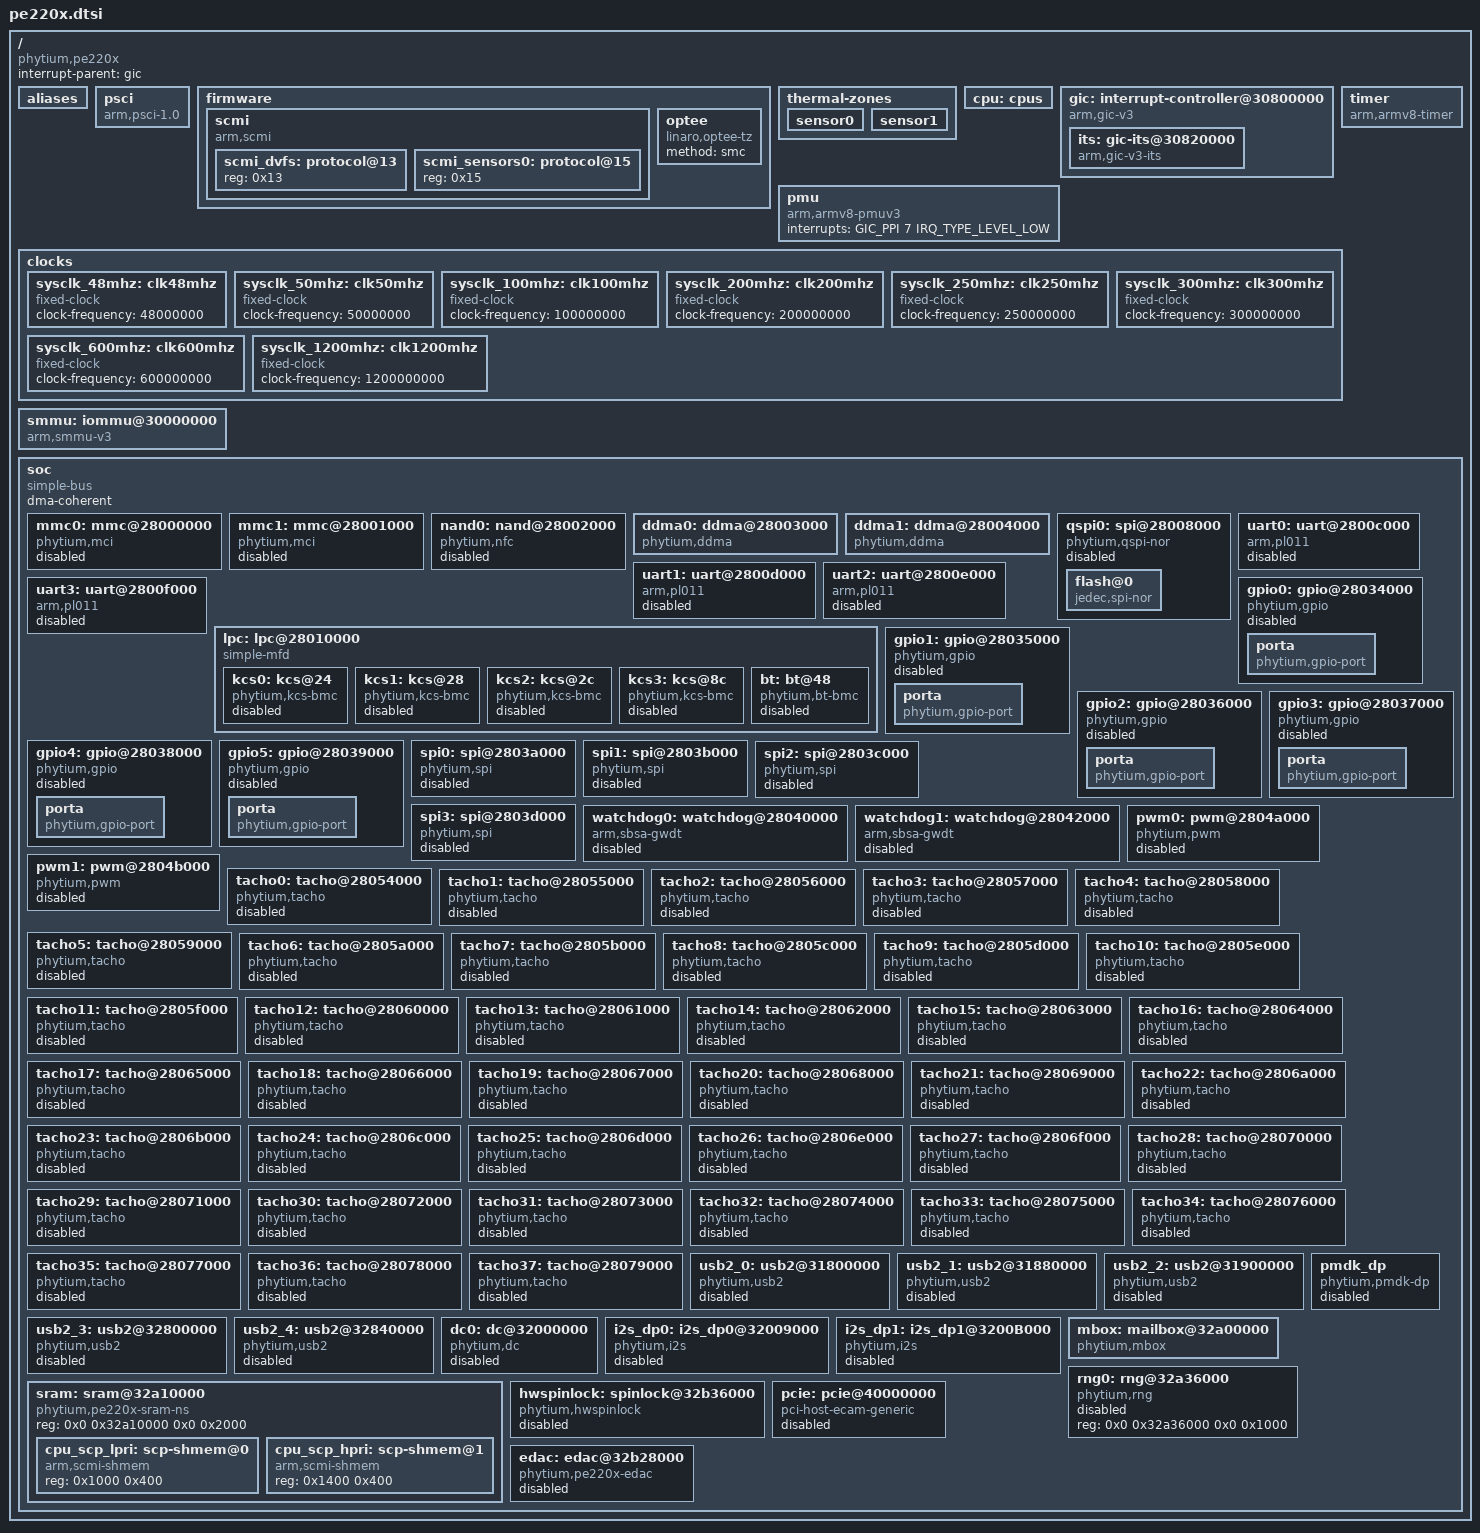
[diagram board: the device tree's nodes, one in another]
// SPDX-License-Identifier: GPL-2.0
/*
 * dts file for Phytium Pe220x SoC
 *
 * Copyright (c) 2021-2023 Phytium Technology Co., Ltd.
 */

#include <dt-bindings/interrupt-controller/arm-gic.h>

/ {
	compatible = "phytium,pe220x";
	interrupt-parent = <&gic>;
	#address-cells = <2>;
	#size-cells = <2>;

	aliases {
		serial0 = &uart0;
		serial1 = &uart1;
		serial2 = &uart2;
		serial3 = &uart3;
	};

	psci {
		compatible   = "arm,psci-1.0";
		method       = "smc";
		cpu_suspend  = <0xc4000001>;
		cpu_off      = <0x84000002>;
		cpu_on       = <0xc4000003>;
		sys_poweroff = <0x84000008>;
		sys_reset    = <0x84000009>;
	};

	firmware {
		scmi: scmi {
			compatible = "arm,scmi";
			mboxes = <&mbox 0>;
			mbox-names = "tx";
			shmem = <&cpu_scp_hpri>;
			#address-cells = <1>;
			#size-cells = <0>;

			scmi_dvfs: protocol@13 {
				reg = <0x13>;
				#clock-cells = <1>;
			};

			scmi_sensors0: protocol@15 {
				reg = <0x15>;
				#thermal-sensor-cells = <1>;
			};
		};
		optee {
			compatible = "linaro,optee-tz";
			method = "smc";
		};
	};

	thermal-zones {
		sensor0 {
			polling-delay-passive = <100>;
			polling-delay = <1000>;
			thermal-sensors = <&scmi_sensors0 0>;
		};

		sensor1 {
			polling-delay-passive = <100>;
			polling-delay = <1000>;
			thermal-sensors = <&scmi_sensors0 1>;
		};
	};

	cpu: cpus {
		#address-cells = <0x2>;
		#size-cells = <0x0>;
	};

	gic: interrupt-controller@30800000 {
		compatible = "arm,gic-v3";
		#interrupt-cells = <3>;
		#address-cells = <2>;
		#size-cells = <2>;
		ranges;
		interrupt-controller;
		reg = <0x0 0x30800000 0 0x20000>,	/* GICD */
			  <0x0 0x30880000 0 0x80000>,	/* GICR */
			  <0x0 0x30840000 0 0x10000>,	/* GICC */
			  <0x0 0x30850000 0 0x10000>,	/* GICH */
			  <0x0 0x30860000 0 0x10000>;	/* GICV */
		interrupts = <GIC_PPI 9 IRQ_TYPE_LEVEL_LOW>;

		its: gic-its@30820000 {
			compatible = "arm,gic-v3-its";
			msi-controller;
			reg = <0x0 0x30820000 0x0 0x20000>;
		};
	};

	pmu {
		compatible = "arm,armv8-pmuv3";
		interrupts = <GIC_PPI 7 IRQ_TYPE_LEVEL_LOW>;
	};

	timer {
		compatible = "arm,armv8-timer";
		interrupts = <GIC_PPI 13 IRQ_TYPE_LEVEL_LOW>,
				 <GIC_PPI 14 IRQ_TYPE_LEVEL_LOW>,
				 <GIC_PPI 11 IRQ_TYPE_LEVEL_LOW>,
				 <GIC_PPI 10 IRQ_TYPE_LEVEL_LOW>;
		clock-frequency = <50000000>;
	};

	clocks {
		#address-cells = <2>;
		#size-cells = <2>;
		ranges;

		sysclk_48mhz: clk48mhz {
			compatible = "fixed-clock";
			#clock-cells = <0>;
			clock-frequency = <48000000>;
		};

		sysclk_50mhz: clk50mhz {
			compatible = "fixed-clock";
			#clock-cells = <0>;
			clock-frequency = <50000000>;
		};

		sysclk_100mhz: clk100mhz {
			compatible = "fixed-clock";
			#clock-cells = <0>;
			clock-frequency = <100000000>;
		};

		sysclk_200mhz: clk200mhz {
			compatible = "fixed-clock";
			#clock-cells = <0>;
			clock-frequency = <200000000>;
		};

		sysclk_250mhz: clk250mhz {
			compatible = "fixed-clock";
			#clock-cells = <0>;
			clock-frequency = <250000000>;
		};

		sysclk_300mhz: clk300mhz {
			compatible = "fixed-clock";
			#clock-cells = <0>;
			clock-frequency = <300000000>;
		};

		sysclk_600mhz: clk600mhz {
			compatible = "fixed-clock";
			#clock-cells = <0>;
			clock-frequency = <600000000>;
		};

		sysclk_1200mhz: clk1200mhz {
			compatible = "fixed-clock";
			#clock-cells = <0>;
			clock-frequency = <1200000000>;
		};
	};

	smmu: iommu@30000000 {
		compatible = "arm,smmu-v3";
		reg = <0x0 0x30000000 0x0 0x800000>;
		interrupts = <GIC_SPI 240 IRQ_TYPE_EDGE_RISING>,
				 <GIC_SPI 239 IRQ_TYPE_EDGE_RISING>,
				 <GIC_SPI 236 IRQ_TYPE_EDGE_RISING>,
				 <GIC_SPI 242 IRQ_TYPE_EDGE_RISING>;
		interrupt-names = "eventq", "priq", "cmdq-sync", "gerror";
		dma-coherent;
		#iommu-cells = <1>;
	};

	soc: soc {
		compatible = "simple-bus";
		#address-cells = <2>;
		#size-cells = <2>;
		dma-coherent;
		ranges;

		mmc0: mmc@28000000 {
			compatible = "phytium,mci";
			reg = <0x0 0x28000000 0x0 0x1000>;
			interrupts = <GIC_SPI 72 IRQ_TYPE_LEVEL_HIGH>;
			clocks = <&sysclk_1200mhz>;
			clock-names = "phytium_mci_clk";
			status = "disabled";
		};

		mmc1: mmc@28001000 {
			compatible = "phytium,mci";
			reg = <0x0 0x28001000 0x0 0x1000>;
			interrupts = <GIC_SPI 73 IRQ_TYPE_LEVEL_HIGH>;
			clocks = <&sysclk_1200mhz>;
			clock-names = "phytium_mci_clk";
			status = "disabled";
		};

		nand0: nand@28002000 {
			compatible = "phytium,nfc";
			reg = <0x0 0x28002000 0x0 0x1000>;
			interrupts = <GIC_SPI 74 IRQ_TYPE_LEVEL_HIGH>;
			status = "disabled";
		};

		ddma0: ddma@28003000 {
			compatible = "phytium,ddma";
			reg = <0x0 0x28003000 0x0 0x1000>;
			interrupts = <GIC_SPI 75 IRQ_TYPE_LEVEL_HIGH>;
			#dma-cells = <2>;
			dma-channels = <8>;
		};

		ddma1: ddma@28004000 {
			compatible = "phytium,ddma";
			reg = <0x0 0x28004000 0x0 0x1000>;
			interrupts = <GIC_SPI 76 IRQ_TYPE_LEVEL_HIGH>;
			#dma-cells = <2>;
			dma-channels = <8>;
		};

		qspi0: spi@28008000 {
			compatible = "phytium,qspi-nor";
			reg = <0x0 0x28008000 0x0	  0x1000>,
				  <0x0		  0x0 0x0 0x0fffffff>;
			reg-names = "qspi", "qspi_mm";
			clocks = <&sysclk_300mhz>;
			status = "disabled";
			#address-cells = <1>;
			#size-cells = <0>;

			flash@0 {
				compatible = "jedec,spi-nor";
				reg = <0x00>;
				spi-rx-bus-width = <1>;
				spi-max-frequency = <50000000>;
			};
		};

		uart0: uart@2800c000 {
			compatible = "arm,pl011","arm,primecell";
			reg = <0x0 0x2800c000 0x0 0x1000>;
			interrupts = <GIC_SPI 83 IRQ_TYPE_LEVEL_HIGH>;
			clocks = <&sysclk_100mhz &sysclk_100mhz>;
			clock-names = "uartclk", "apb_pclk";
			status = "disabled";
		};

		uart1: uart@2800d000 {
			compatible = "arm,pl011","arm,primecell";
			reg = <0x0 0x2800d000 0x0 0x1000>;
			interrupts = <GIC_SPI 84 IRQ_TYPE_LEVEL_HIGH>;
			clocks = <&sysclk_100mhz &sysclk_100mhz>;
			clock-names = "uartclk", "apb_pclk";
			status = "disabled";
		};

		uart2: uart@2800e000 {
			compatible = "arm,pl011","arm,primecell";
			reg = <0x0 0x2800e000 0x0 0x1000>;
			interrupts = <GIC_SPI 85 IRQ_TYPE_LEVEL_HIGH>;
			clocks = <&sysclk_100mhz &sysclk_100mhz>;
			clock-names = "uartclk", "apb_pclk";
			status = "disabled";
		};

		uart3: uart@2800f000 {
			compatible = "arm,pl011","arm,primecell";
			reg = <0x0 0x2800f000 0x0 0x1000>;
			interrupts = <GIC_SPI 86 IRQ_TYPE_LEVEL_HIGH>;
			clocks = <&sysclk_100mhz &sysclk_100mhz>;
			clock-names = "uartclk", "apb_pclk";
			status = "disabled";
		};

		lpc: lpc@28010000 {
			compatible = "simple-mfd", "syscon";
			reg = <0x0 0x28010000 0x0 0x1000>;
			reg-io-width = <4>;

			#address-cells = <1>;
			#size-cells = <1>;
			ranges = <0x0 0x0 0x28010000 0x1000>;

			kcs0: kcs@24 {
				compatible = "phytium,kcs-bmc";
				reg = <0x24 0x1>, <0x30 0x1>, <0x3c 0x1>;
				interrupts = <GIC_SPI 88 IRQ_TYPE_LEVEL_HIGH>;
				status = "disabled";
			};

			kcs1: kcs@28 {
				compatible = "phytium,kcs-bmc";
				reg = <0x28 0x1>, <0x34 0x1>, <0x40 0x1>;
				interrupts = <GIC_SPI 88 IRQ_TYPE_LEVEL_HIGH>;
				status = "disabled";
			};

			kcs2: kcs@2c {
				compatible = "phytium,kcs-bmc";
				reg = <0x2c 0x1>, <0x38 0x1>, <0x44 0x1>;
				interrupts = <GIC_SPI 88 IRQ_TYPE_LEVEL_HIGH>;
				status = "disabled";
			};

			kcs3: kcs@8c {
				compatible = "phytium,kcs-bmc";
				reg = <0x8c 0x1>, <0x90 0x1>, <0x94 0x1>;
				interrupts = <GIC_SPI 88 IRQ_TYPE_LEVEL_HIGH>;
				status = "disabled";
			};

			bt: bt@48 {
				compatible = "phytium,bt-bmc";
				reg = <0x48 0x20>;
				interrupts = <GIC_SPI 88 IRQ_TYPE_LEVEL_HIGH>;
				status = "disabled";
			};
		};

		/* MIO */

		gpio0: gpio@28034000 {
			compatible = "phytium,gpio";
			reg = <0x0 0x28034000 0x0 0x1000>;
			interrupts = <GIC_SPI 108 IRQ_TYPE_LEVEL_HIGH>,
					 <GIC_SPI 109 IRQ_TYPE_LEVEL_HIGH>,
					 <GIC_SPI 110 IRQ_TYPE_LEVEL_HIGH>,
					 <GIC_SPI 111 IRQ_TYPE_LEVEL_HIGH>,
					 <GIC_SPI 112 IRQ_TYPE_LEVEL_HIGH>,
					 <GIC_SPI 113 IRQ_TYPE_LEVEL_HIGH>,
					 <GIC_SPI 114 IRQ_TYPE_LEVEL_HIGH>,
					 <GIC_SPI 115 IRQ_TYPE_LEVEL_HIGH>,
					 <GIC_SPI 116 IRQ_TYPE_LEVEL_HIGH>,
					 <GIC_SPI 117 IRQ_TYPE_LEVEL_HIGH>,
					 <GIC_SPI 118 IRQ_TYPE_LEVEL_HIGH>,
					 <GIC_SPI 119 IRQ_TYPE_LEVEL_HIGH>,
					 <GIC_SPI 120 IRQ_TYPE_LEVEL_HIGH>,
					 <GIC_SPI 121 IRQ_TYPE_LEVEL_HIGH>,
					 <GIC_SPI 122 IRQ_TYPE_LEVEL_HIGH>,
					 <GIC_SPI 123 IRQ_TYPE_LEVEL_HIGH>;
			gpio-controller;
			#gpio-cells = <2>;
			#address-cells = <1>;
			#size-cells = <0>;
			status = "disabled";

			porta {
				compatible = "phytium,gpio-port";
				reg = <0>;
				ngpios = <16>;
			};
		};

		gpio1: gpio@28035000 {
			compatible = "phytium,gpio";
			reg = <0x0 0x28035000 0x0 0x1000>;
			interrupts = <GIC_SPI 124 IRQ_TYPE_LEVEL_HIGH>,
					 <GIC_SPI 125 IRQ_TYPE_LEVEL_HIGH>,
					 <GIC_SPI 126 IRQ_TYPE_LEVEL_HIGH>,
					 <GIC_SPI 127 IRQ_TYPE_LEVEL_HIGH>,
					 <GIC_SPI 128 IRQ_TYPE_LEVEL_HIGH>,
					 <GIC_SPI 129 IRQ_TYPE_LEVEL_HIGH>,
					 <GIC_SPI 130 IRQ_TYPE_LEVEL_HIGH>,
					 <GIC_SPI 131 IRQ_TYPE_LEVEL_HIGH>,
					 <GIC_SPI 132 IRQ_TYPE_LEVEL_HIGH>,
					 <GIC_SPI 133 IRQ_TYPE_LEVEL_HIGH>,
					 <GIC_SPI 134 IRQ_TYPE_LEVEL_HIGH>,
					 <GIC_SPI 135 IRQ_TYPE_LEVEL_HIGH>,
					 <GIC_SPI 136 IRQ_TYPE_LEVEL_HIGH>,
					 <GIC_SPI 137 IRQ_TYPE_LEVEL_HIGH>,
					 <GIC_SPI 138 IRQ_TYPE_LEVEL_HIGH>,
					 <GIC_SPI 139 IRQ_TYPE_LEVEL_HIGH>;
			gpio-controller;
			#gpio-cells = <2>;
			#address-cells = <1>;
			#size-cells = <0>;
			status = "disabled";

			porta {
				compatible = "phytium,gpio-port";
				reg = <0>;
				ngpios = <16>;
			};
		};

		gpio2: gpio@28036000 {
			compatible = "phytium,gpio";
			reg = <0x0 0x28036000 0x0 0x1000>;
			interrupts = <GIC_SPI 140 IRQ_TYPE_LEVEL_HIGH>,
					 <GIC_SPI 141 IRQ_TYPE_LEVEL_HIGH>,
					 <GIC_SPI 142 IRQ_TYPE_LEVEL_HIGH>,
					 <GIC_SPI 143 IRQ_TYPE_LEVEL_HIGH>,
					 <GIC_SPI 144 IRQ_TYPE_LEVEL_HIGH>,
					 <GIC_SPI 145 IRQ_TYPE_LEVEL_HIGH>,
					 <GIC_SPI 146 IRQ_TYPE_LEVEL_HIGH>,
					 <GIC_SPI 147 IRQ_TYPE_LEVEL_HIGH>,
					 <GIC_SPI 148 IRQ_TYPE_LEVEL_HIGH>,
					 <GIC_SPI 149 IRQ_TYPE_LEVEL_HIGH>,
					 <GIC_SPI 150 IRQ_TYPE_LEVEL_HIGH>,
					 <GIC_SPI 151 IRQ_TYPE_LEVEL_HIGH>,
					 <GIC_SPI 152 IRQ_TYPE_LEVEL_HIGH>,
					 <GIC_SPI 153 IRQ_TYPE_LEVEL_HIGH>,
					 <GIC_SPI 154 IRQ_TYPE_LEVEL_HIGH>,
					 <GIC_SPI 155 IRQ_TYPE_LEVEL_HIGH>;
			gpio-controller;
			#gpio-cells = <2>;
			#address-cells = <1>;
			#size-cells = <0>;
			status = "disabled";

			porta {
				compatible = "phytium,gpio-port";
				reg = <0>;
				ngpios = <16>;
			};
		};

		gpio3: gpio@28037000 {
			compatible = "phytium,gpio";
			reg = <0x0 0x28037000 0x0 0x1000>;
			interrupts = <GIC_SPI 156 IRQ_TYPE_LEVEL_HIGH>;
			gpio-controller;
			#gpio-cells = <2>;
			#address-cells = <1>;
			#size-cells = <0>;
			status = "disabled";

			porta {
				compatible = "phytium,gpio-port";
				reg = <0>;
				ngpios = <16>;
			};
		};

		gpio4: gpio@28038000 {
			compatible = "phytium,gpio";
			reg = <0x0 0x28038000 0x0 0x1000>;
			interrupts = <GIC_SPI 157 IRQ_TYPE_LEVEL_HIGH>;
			gpio-controller;
			#gpio-cells = <2>;
			#address-cells = <1>;
			#size-cells = <0>;
			status = "disabled";

			porta {
				compatible = "phytium,gpio-port";
				reg = <0>;
				ngpios = <16>;
			};
		};

		gpio5: gpio@28039000 {
			compatible = "phytium,gpio";
			reg = <0x0 0x28039000 0x0 0x1000>;
			interrupts = <GIC_SPI 158 IRQ_TYPE_LEVEL_HIGH>;
			gpio-controller;
			#gpio-cells = <2>;
			#address-cells = <1>;
			#size-cells = <0>;
			status = "disabled";

			porta {
				compatible = "phytium,gpio-port";
				reg = <0>;
				ngpios = <16>;
			};
		};

		spi0: spi@2803a000 {
			compatible = "phytium,spi";
			reg = <0x0 0x2803a000 0x0 0x1000>;
			interrupts = <GIC_SPI 159 IRQ_TYPE_LEVEL_HIGH>;
			clocks = <&sysclk_50mhz>;
			num-cs = <4>;
			#address-cells = <1>;
			#size-cells = <0>;
			status = "disabled";
		};

		spi1: spi@2803b000 {
			compatible = "phytium,spi";
			reg = <0x0 0x2803b000 0x0 0x1000>;
			interrupts = <GIC_SPI 160 IRQ_TYPE_LEVEL_HIGH>;
			clocks = <&sysclk_50mhz>;
			num-cs = <4>;
			#address-cells = <1>;
			#size-cells = <0>;
			status = "disabled";
		};

		spi2: spi@2803c000 {
			compatible = "phytium,spi";
			reg = <0x0 0x2803c000 0x0 0x1000>;
			interrupts = <GIC_SPI 161 IRQ_TYPE_LEVEL_HIGH>;
			clocks = <&sysclk_50mhz>;
			num-cs = <4>;
			#address-cells = <1>;
			#size-cells = <0>;
			status = "disabled";
		};

		spi3: spi@2803d000 {
			compatible = "phytium,spi";
			reg = <0x0 0x2803d000 0x0 0x1000>;
			interrupts = <GIC_SPI 162 IRQ_TYPE_LEVEL_HIGH>;
			clocks = <&sysclk_50mhz>;
			num-cs = <4>;
			#address-cells = <1>;
			#size-cells = <0>;
			status = "disabled";
		};

		watchdog0: watchdog@28040000 {
			compatible = "arm,sbsa-gwdt";
			reg = <0x0 0x28041000 0x0 0x1000>,
				  <0x0 0x28040000 0x0 0x1000>;
			interrupts = <GIC_SPI 164 IRQ_TYPE_LEVEL_HIGH>;
			timeout-sec = <30>;
			status = "disabled";
		};

		watchdog1: watchdog@28042000 {
			compatible = "arm,sbsa-gwdt";
			reg = <0x0 0x28043000 0x0 0x1000>,
				  <0x0 0x28042000 0x0 0x1000>;
			interrupts = <GIC_SPI 165 IRQ_TYPE_LEVEL_HIGH>;
			timeout-sec = <30>;
			status = "disabled";
		};

		pwm0: pwm@2804a000 {
			compatible = "phytium,pwm";
			reg = <0x0 0x2804a000 0x0 0x1000>;
			interrupts = <GIC_SPI 173 IRQ_TYPE_LEVEL_HIGH>;
			clocks = <&sysclk_50mhz>;
			status = "disabled";
		};

		pwm1: pwm@2804b000 {
			compatible = "phytium,pwm";
			reg = <0x0 0x2804b000 0x0 0x1000>;
			interrupts = <GIC_SPI 174 IRQ_TYPE_LEVEL_HIGH>;
			clocks = <&sysclk_50mhz>;
			status = "disabled";
		};

		tacho0: tacho@28054000 {
			compatible = "phytium,tacho";
			reg = <0x0 0x28054000 0x0 0x1000>;
			interrupts = <GIC_SPI 194 IRQ_TYPE_LEVEL_HIGH>;
			clocks = <&sysclk_50mhz >;
			status = "disabled";
		};

		tacho1: tacho@28055000 {
			compatible = "phytium,tacho";
			reg = <0x0 0x28055000 0x0 0x1000>;
			interrupts = <GIC_SPI 195 IRQ_TYPE_LEVEL_HIGH>;
			clocks = <&sysclk_50mhz >;
			status = "disabled";
		};

		tacho2: tacho@28056000 {
			compatible = "phytium,tacho";
			reg = <0x0 0x28056000 0x0 0x1000>;
			interrupts = <GIC_SPI 196 IRQ_TYPE_LEVEL_HIGH>;
			clocks = <&sysclk_50mhz >;
			status = "disabled";
		};

		tacho3: tacho@28057000 {
			compatible = "phytium,tacho";
			reg = <0x0 0x28057000 0x0 0x1000>;
			interrupts = <GIC_SPI 197 IRQ_TYPE_LEVEL_HIGH>;
			clocks = <&sysclk_50mhz >;
			status = "disabled";
		};

		tacho4: tacho@28058000 {
			compatible = "phytium,tacho";
			reg = <0x0 0x28058000 0x0 0x1000>;
			interrupts = <GIC_SPI 198 IRQ_TYPE_LEVEL_HIGH>;
			clocks = <&sysclk_50mhz >;
			status = "disabled";
		};

		tacho5: tacho@28059000 {
			compatible = "phytium,tacho";
			reg = <0x0 0x28059000 0x0 0x1000>;
			interrupts = <GIC_SPI 199 IRQ_TYPE_LEVEL_HIGH>;
			clocks = <&sysclk_50mhz >;
			status = "disabled";
		};

		tacho6: tacho@2805a000 {
			compatible = "phytium,tacho";
			reg = <0x0 0x2805a000 0x0 0x1000>;
			interrupts = <GIC_SPI 200 IRQ_TYPE_LEVEL_HIGH>;
			clocks = <&sysclk_50mhz >;
			status = "disabled";
		};

		tacho7: tacho@2805b000 {
			compatible = "phytium,tacho";
			reg = <0x0 0x2805b000 0x0 0x1000>;
			interrupts = <GIC_SPI 201 IRQ_TYPE_LEVEL_HIGH>;
			clocks = <&sysclk_50mhz >;
			status = "disabled";
		};

		tacho8: tacho@2805c000 {
			compatible = "phytium,tacho";
			reg = <0x0 0x2805c000 0x0 0x1000>;
			interrupts = <GIC_SPI 202 IRQ_TYPE_LEVEL_HIGH>;
			clocks = <&sysclk_50mhz >;
			status = "disabled";
		};

		tacho9: tacho@2805d000 {
			compatible = "phytium,tacho";
			reg = <0x0 0x2805d000 0x0 0x1000>;
			interrupts = <GIC_SPI 203 IRQ_TYPE_LEVEL_HIGH>;
			clocks = <&sysclk_50mhz >;
			status = "disabled";
		};

		tacho10: tacho@2805e000 {
			compatible = "phytium,tacho";
			reg = <0x0 0x2805e000 0x0 0x1000>;
			interrupts = <GIC_SPI 204 IRQ_TYPE_LEVEL_HIGH>;
			clocks = <&sysclk_50mhz >;
			status = "disabled";
		};

		tacho11: tacho@2805f000 {
			compatible = "phytium,tacho";
			reg = <0x0 0x2805f000 0x0 0x1000>;
			interrupts = <GIC_SPI 205 IRQ_TYPE_LEVEL_HIGH>;
			clocks = <&sysclk_50mhz >;
			status = "disabled";
		};

		tacho12: tacho@28060000 {
			compatible = "phytium,tacho";
			reg = <0x0 0x28060000 0x0 0x1000>;
			interrupts = <GIC_SPI 206 IRQ_TYPE_LEVEL_HIGH>;
			clocks = <&sysclk_50mhz >;
			status = "disabled";
		};

		tacho13: tacho@28061000 {
			compatible = "phytium,tacho";
			reg = <0x0 0x28061000 0x0 0x1000>;
			interrupts = <GIC_SPI 207 IRQ_TYPE_LEVEL_HIGH>;
			clocks = <&sysclk_50mhz >;
			status = "disabled";
		};

		tacho14: tacho@28062000 {
			compatible = "phytium,tacho";
			reg = <0x0 0x28062000 0x0 0x1000>;
			interrupts = <GIC_SPI 208 IRQ_TYPE_LEVEL_HIGH>;
			clocks = <&sysclk_50mhz >;
			status = "disabled";
		};

		tacho15: tacho@28063000 {
			compatible = "phytium,tacho";
			reg = <0x0 0x28063000 0x0 0x1000>;
			interrupts = <GIC_SPI 209 IRQ_TYPE_LEVEL_HIGH>;
			clocks = <&sysclk_50mhz >;
			status = "disabled";
		};

		tacho16: tacho@28064000 {
			compatible = "phytium,tacho";
			reg = <0x0 0x28064000 0x0 0x1000>;
			interrupts = <GIC_SPI 210 IRQ_TYPE_LEVEL_HIGH>;
			clocks = <&sysclk_50mhz >;
			status = "disabled";
		};

		tacho17: tacho@28065000 {
			compatible = "phytium,tacho";
			reg = <0x0 0x28065000 0x0 0x1000>;
			interrupts = <GIC_SPI 211 IRQ_TYPE_LEVEL_HIGH>;
			clocks = <&sysclk_50mhz >;
			status = "disabled";
		};

		tacho18: tacho@28066000 {
			compatible = "phytium,tacho";
			reg = <0x0 0x28066000 0x0 0x1000>;
			interrupts = <GIC_SPI 212 IRQ_TYPE_LEVEL_HIGH>;
			clocks = <&sysclk_50mhz >;
			status = "disabled";
		};

		tacho19: tacho@28067000 {
			compatible = "phytium,tacho";
			reg = <0x0 0x28067000 0x0 0x1000>;
			interrupts = <GIC_SPI 213 IRQ_TYPE_LEVEL_HIGH>;
			clocks = <&sysclk_50mhz >;
			status = "disabled";
		};

		tacho20: tacho@28068000 {
			compatible = "phytium,tacho";
			reg = <0x0 0x28068000 0x0 0x1000>;
			interrupts = <GIC_SPI 214 IRQ_TYPE_LEVEL_HIGH>;
			clocks = <&sysclk_50mhz >;
			status = "disabled";
		};

		tacho21: tacho@28069000 {
			compatible = "phytium,tacho";
			reg = <0x0 0x28069000 0x0 0x1000>;
			interrupts = <GIC_SPI 215 IRQ_TYPE_LEVEL_HIGH>;
			clocks = <&sysclk_50mhz >;
			status = "disabled";
		};

		tacho22: tacho@2806a000 {
			compatible = "phytium,tacho";
			reg = <0x0 0x2806a000 0x0 0x1000>;
			interrupts = <GIC_SPI 216 IRQ_TYPE_LEVEL_HIGH>;
			clocks = <&sysclk_50mhz >;
			status = "disabled";
		};

		tacho23: tacho@2806b000 {
			compatible = "phytium,tacho";
			reg = <0x0 0x2806b000 0x0 0x1000>;
			interrupts = <GIC_SPI 217 IRQ_TYPE_LEVEL_HIGH>;
			clocks = <&sysclk_50mhz >;
			status = "disabled";
		};

		tacho24: tacho@2806c000 {
			compatible = "phytium,tacho";
			reg = <0x0 0x2806c000 0x0 0x1000>;
			interrupts = <GIC_SPI 218 IRQ_TYPE_LEVEL_HIGH>;
			clocks = <&sysclk_50mhz >;
			status = "disabled";
		};

		tacho25: tacho@2806d000 {
			compatible = "phytium,tacho";
			reg = <0x0 0x2806d000 0x0 0x1000>;
			interrupts = <GIC_SPI 219 IRQ_TYPE_LEVEL_HIGH>;
			clocks = <&sysclk_50mhz >;
			status = "disabled";
		};

		tacho26: tacho@2806e000 {
			compatible = "phytium,tacho";
			reg = <0x0 0x2806e000 0x0 0x1000>;
			interrupts = <GIC_SPI 220 IRQ_TYPE_LEVEL_HIGH>;
			clocks = <&sysclk_50mhz >;
			status = "disabled";
		};

		tacho27: tacho@2806f000 {
			compatible = "phytium,tacho";
			reg = <0x0 0x2806f000 0x0 0x1000>;
			interrupts = <GIC_SPI 221 IRQ_TYPE_LEVEL_HIGH>;
			clocks = <&sysclk_50mhz >;
			status = "disabled";
		};

		tacho28: tacho@28070000 {
			compatible = "phytium,tacho";
			reg = <0x0 0x28070000 0x0 0x1000>;
			interrupts = <GIC_SPI 222 IRQ_TYPE_LEVEL_HIGH>;
			clocks = <&sysclk_50mhz >;
			status = "disabled";
		};

		tacho29: tacho@28071000 {
			compatible = "phytium,tacho";
			reg = <0x0 0x28071000 0x0 0x1000>;
			interrupts = <GIC_SPI 223 IRQ_TYPE_LEVEL_HIGH>;
			clocks = <&sysclk_50mhz >;
			status = "disabled";
		};

		tacho30: tacho@28072000 {
			compatible = "phytium,tacho";
			reg = <0x0 0x28072000 0x0 0x1000>;
			interrupts = <GIC_SPI 224 IRQ_TYPE_LEVEL_HIGH>;
			clocks = <&sysclk_50mhz >;
			status = "disabled";
		};

		tacho31: tacho@28073000 {
			compatible = "phytium,tacho";
			reg = <0x0 0x28073000 0x0 0x1000>;
			interrupts = <GIC_SPI 225 IRQ_TYPE_LEVEL_HIGH>;
			clocks = <&sysclk_50mhz >;
			status = "disabled";
		};

		tacho32: tacho@28074000 {
			compatible = "phytium,tacho";
			reg = <0x0 0x28074000 0x0 0x1000>;
			interrupts = <GIC_SPI 226 IRQ_TYPE_LEVEL_HIGH>;
			clocks = <&sysclk_50mhz >;
			status = "disabled";
		};

		tacho33: tacho@28075000 {
			compatible = "phytium,tacho";
			reg = <0x0 0x28075000 0x0 0x1000>;
			interrupts = <GIC_SPI 227 IRQ_TYPE_LEVEL_HIGH>;
			clocks = <&sysclk_50mhz >;
			status = "disabled";
		};

		tacho34: tacho@28076000 {
			compatible = "phytium,tacho";
			reg = <0x0 0x28076000 0x0 0x1000>;
			interrupts = <GIC_SPI 228 IRQ_TYPE_LEVEL_HIGH>;
			clocks = <&sysclk_50mhz >;
			status = "disabled";
		};

		tacho35: tacho@28077000 {
			compatible = "phytium,tacho";
			reg = <0x0 0x28077000 0x0 0x1000>;
			interrupts = <GIC_SPI 229 IRQ_TYPE_LEVEL_HIGH>;
			clocks = <&sysclk_50mhz >;
			status = "disabled";
		};

		tacho36: tacho@28078000 {
			compatible = "phytium,tacho";
			reg = <0x0 0x28078000 0x0 0x1000>;
			interrupts = <GIC_SPI 230 IRQ_TYPE_LEVEL_HIGH>;
			clocks = <&sysclk_50mhz >;
			status = "disabled";
		};

		tacho37: tacho@28079000 {
			compatible = "phytium,tacho";
			reg = <0x0 0x28079000 0x0 0x1000>;
			interrupts = <GIC_SPI 231 IRQ_TYPE_LEVEL_HIGH>;
			clocks = <&sysclk_50mhz >;
			status = "disabled";
		};

		usb2_0: usb2@31800000 { /* usb_vhub0 USB2_P2 only otg mode */
			compatible = "phytium,usb2";
			reg = <0x0 0x31800000 0x0 0x80000>,
				  <0x0 0x31990000 0x0 0x10000>;
			interrupts = <GIC_SPI 32 IRQ_TYPE_LEVEL_HIGH>;
			status = "disabled";
		};

		usb2_1: usb2@31880000 { /* usb_vhub1 USB2_P2 */
			compatible = "phytium,usb2";
			reg = <0x0 0x31880000 0x0 0x80000>,
				  <0x0 0x319a0000 0x0 0x10000>;
			interrupts = <GIC_SPI 33 IRQ_TYPE_LEVEL_HIGH>;
			status = "disabled";
		};

		usb2_2: usb2@31900000 { /* usb_vhub2 USB2_P2 */
			compatible = "phytium,usb2";
			reg = <0x0 0x31900000 0x0 0x80000>,
				  <0x0 0x319b0000 0x0 0x10000>;
			interrupts = <GIC_SPI 34 IRQ_TYPE_LEVEL_HIGH>;
			status = "disabled";
		};

		usb2_3: usb2@32800000 { /* USB2_0 controller registers USB2_P3 */
			compatible = "phytium,usb2";
			reg = <0x0 0x32800000 0x0 0x40000>,
				  <0x0 0x32880000 0x0 0x40000>; /* USB2_0 UIB registers */
			interrupts = <GIC_SPI 14 IRQ_TYPE_LEVEL_HIGH>;
			status = "disabled";
		};

		usb2_4: usb2@32840000 { /* USB2_1 controller registers USB2_P4 */
			compatible = "phytium,usb2";
			reg = <0x0 0x32840000 0x0 0x40000>,
				  <0x0 0x328c0000 0x0 0x40000>; /* USB2_1 UIB registers */
			interrupts = <GIC_SPI 15 IRQ_TYPE_LEVEL_HIGH>;
			status = "disabled";
		};

		dc0: dc@32000000 {
			compatible = "phytium,dc";
			reg = <0x0 0x32000000 0x0 0x8000>;
			interrupts = <GIC_SPI 44 IRQ_TYPE_LEVEL_HIGH>;
			status = "disabled";
		};

		i2s_dp0: i2s_dp0@32009000 {
			compatible = "phytium,i2s";
			reg = <0x0 0x32009000 0x0 0x1000>,
				  <0x0 0x32008000 0x0 0x1000>;
			interrupts = <GIC_SPI 47 IRQ_TYPE_LEVEL_HIGH>;
			clocks = <&sysclk_600mhz>;
			clock-names = "i2s_clk";
			dai-name = "phytium-i2s-dp0";
			status = "disabled";
		};

		i2s_dp1: i2s_dp1@3200B000 {
			compatible = "phytium,i2s";
			reg = <0x0 0x3200B000 0x0 0x1000>,
				  <0x0 0x3200A000 0x0 0x1000>;
			interrupts = <GIC_SPI 48 IRQ_TYPE_LEVEL_HIGH>;
			clocks = <&sysclk_600mhz>;
			clock-names = "i2s_clk";
			dai-name = "phytium-i2s-dp1";
			status = "disabled";
		};

		pmdk_dp: pmdk_dp {
			compatible = "phytium,pmdk-dp";
			status = "disabled";
		};

		mbox: mailbox@32a00000 {
			compatible = "phytium,mbox";
			reg = <0x0 0x32a00000 0x0 0x1000>;
			interrupts = <GIC_SPI 22 IRQ_TYPE_LEVEL_HIGH>;
			#mbox-cells = <1>;
		};

		rng0: rng@32a36000 {
			compatible = "phytium,rng";
			reg = <0x0 0x32a36000 0x0 0x1000>;
			status = "disabled";
		};

		sram: sram@32a10000 {
			compatible = "phytium,pe220x-sram-ns", "mmio-sram";
			reg = <0x0 0x32a10000 0x0 0x2000>;

			#address-cells = <1>;
			#size-cells = <1>;
			ranges = <0x0 0x0 0x32a10000 0x2000>;

			cpu_scp_lpri: scp-shmem@0 {
				compatible = "arm,scmi-shmem";
				reg = <0x1000 0x400>;
			};

			cpu_scp_hpri: scp-shmem@1 {
				compatible = "arm,scmi-shmem";
				reg = <0x1400 0x400>;
			};
		};

		hwspinlock: spinlock@32b36000 {
			compatible = "phytium,hwspinlock";
			reg = <0x0 0x32b36000 0x0 0x1000>;
			#hwlock-cells = <1>;
			nr-locks = <32>;
			status = "disabled";
		};

		pcie: pcie@40000000 {
			compatible = "pci-host-ecam-generic";
			device_type = "pci";
			#address-cells = <3>;
			#size-cells = <2>;
			#interrupt-cells = <1>;
			reg = <0x0 0x40000000 0x0 0x10000000>;
			msi-parent = <&its>;
			bus-range = <0x0 0xff>;
			interrupt-map-mask = <0x0 0x0 0x0 0x7>;
			interrupt-map = <0x0 0x0 0x0 0x1 &gic 0x0 0x0 GIC_SPI 4 IRQ_TYPE_LEVEL_HIGH>,
					<0x0 0x0 0x0 0x2 &gic 0x0 0x0 GIC_SPI 5 IRQ_TYPE_LEVEL_HIGH>,
					<0x0 0x0 0x0 0x3 &gic 0x0 0x0 GIC_SPI 6 IRQ_TYPE_LEVEL_HIGH>,
					<0x0 0x0 0x0 0x4 &gic 0x0 0x0 GIC_SPI 7 IRQ_TYPE_LEVEL_HIGH>;
			ranges = <0x01000000 0x00 0x00000000 0x0  0x50000000  0x0  0x00f00000>,
				 <0x02000000 0x00 0x58000000 0x0  0x58000000  0x0  0x28000000>,
				 <0x03000000 0x10 0x00000000 0x10 0x00000000 0x10  0x00000000>;
			iommu-map = <0x0 &smmu 0x0 0x10000>;
			status = "disabled";
		};

		edac: edac@32b28000 {
			compatible = "phytium,pe220x-edac";
			reg = <0x0 0x32b28000 0x0 0x1000>,
				<0x0 0x31400000 0x0 0x1000>,
				<0x0 0x31401000 0x0 0x1000>;
			interrupts = <GIC_SPI 0 IRQ_TYPE_LEVEL_HIGH>,
					<GIC_SPI 1 IRQ_TYPE_LEVEL_HIGH>;
			status = "disabled";
		};
	};
};
